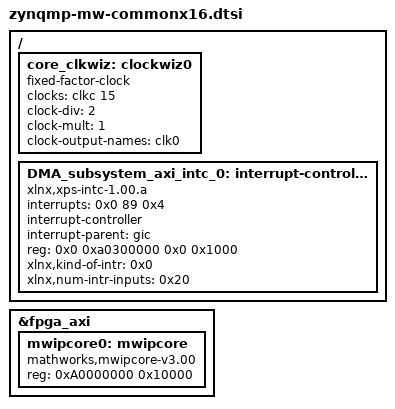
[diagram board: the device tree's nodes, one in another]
/{
	core_clkwiz: clockwiz0 {
		compatible = "fixed-factor-clock";
		clocks = <&clkc 15>;
		#clock-cells = <1>;
		clock-div = <2>;
		clock-mult = <1>;
		clock-output-names = "clk0";
	};
	DMA_subsystem_axi_intc_0: interrupt-controller {
		#interrupt-cells = <2>;
		compatible = "xlnx,xps-intc-1.00.a";
		interrupts = <0x0 89 0x4>;
		interrupt-controller;
                interrupt-parent = <&gic>;
		reg = <0x0 0xa0300000 0x0 0x1000>;
		xlnx,kind-of-intr = <0x0>;
		xlnx,num-intr-inputs = <0x20>;
	};
};

&fpga_axi {
		mwipcore0: mwipcore {
			compatible = "mathworks,mwipcore-v3.00";
			reg = <0xA0000000 0x10000>;
		};
};

